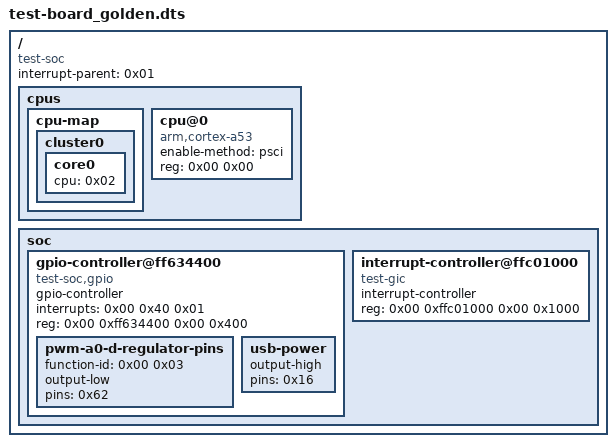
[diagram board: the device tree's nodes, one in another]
/dts-v1/;

/ {
	#address-cells = <0x02>;
	#size-cells = <0x02>;
	compatible = "test-soc";
	interrupt-parent = <0x01>;

	cpus {
		#address-cells = <0x02>;
		#size-cells = <0x00>;

		cpu-map {

			cluster0 {

				core0 {
					cpu = <0x02>;
				};
			};
		};

		cpu@0 {
			compatible = "arm,cortex-a53\0arm,armv8";
			device_type = "cpu";
			enable-method = "psci";
			phandle = <0x02>;
			reg = <0x00 0x00>;
		};
	};

	soc {
		#address-cells = <0x02>;
		#size-cells = <0x02>;
		ranges;

		gpio-controller@ff634400 {
			#gpio-cells = <0x02>;
			compatible = "test-soc,gpio";
			gpio-controller;
			interrupts = <0x00 0x40 0x01>;
			reg = <0x00 0xff634400 0x00 0x400>;

			pwm-a0-d-regulator-pins {
				function-id = <0x00 0x03>;
				output-low;
				pins = <0x62>;
			};

			usb-power {
				output-high;
				pins = <0x16>;
			};
		};

		interrupt-controller@ffc01000 {
			#address-cells = <0x00>;
			#interrupt-cells = <0x03>;
			compatible = "test-gic";
			interrupt-controller;
			phandle = <0x01>;
			reg = <0x00 0xffc01000 0x00 0x1000>;
		};
	};
};
